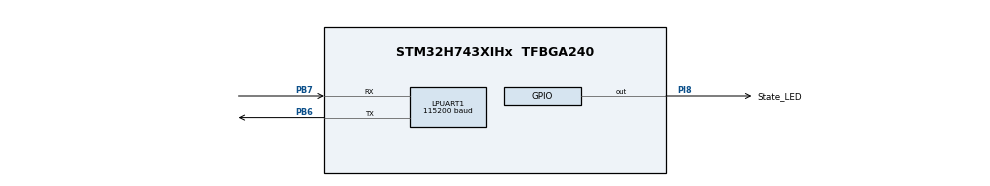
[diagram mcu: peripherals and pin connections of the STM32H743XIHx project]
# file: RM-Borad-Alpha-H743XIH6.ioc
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Bdma.LPUART1_RX.0.Direction=DMA_PERIPH_TO_MEMORY
Bdma.LPUART1_RX.0.EventEnable=DISABLE
Bdma.LPUART1_RX.0.Instance=BDMA_Channel0
Bdma.LPUART1_RX.0.MemDataAlignment=DMA_MDATAALIGN_BYTE
Bdma.LPUART1_RX.0.MemInc=DMA_MINC_ENABLE
Bdma.LPUART1_RX.0.Mode=DMA_NORMAL
Bdma.LPUART1_RX.0.PeriphDataAlignment=DMA_PDATAALIGN_BYTE
Bdma.LPUART1_RX.0.PeriphInc=DMA_PINC_DISABLE
Bdma.LPUART1_RX.0.Polarity=HAL_DMAMUX_REQ_GEN_RISING
Bdma.LPUART1_RX.0.Priority=DMA_PRIORITY_LOW
Bdma.LPUART1_RX.0.RequestNumber=1
Bdma.LPUART1_RX.0.SignalID=NONE
Bdma.LPUART1_RX.0.SyncEnable=DISABLE
Bdma.LPUART1_RX.0.SyncPolarity=HAL_DMAMUX_SYNC_NO_EVENT
Bdma.LPUART1_RX.0.SyncRequestNumber=1
Bdma.LPUART1_RX.0.SyncSignalID=NONE
Bdma.LPUART1_TX.1.Direction=DMA_MEMORY_TO_PERIPH
Bdma.LPUART1_TX.1.EventEnable=DISABLE
Bdma.LPUART1_TX.1.Instance=BDMA_Channel1
Bdma.LPUART1_TX.1.MemDataAlignment=DMA_MDATAALIGN_BYTE
Bdma.LPUART1_TX.1.MemInc=DMA_MINC_ENABLE
Bdma.LPUART1_TX.1.Mode=DMA_NORMAL
Bdma.LPUART1_TX.1.PeriphDataAlignment=DMA_PDATAALIGN_BYTE
Bdma.LPUART1_TX.1.PeriphInc=DMA_PINC_DISABLE
Bdma.LPUART1_TX.1.Polarity=HAL_DMAMUX_REQ_GEN_RISING
Bdma.LPUART1_TX.1.Priority=DMA_PRIORITY_LOW
Bdma.LPUART1_TX.1.RequestNumber=1
Bdma.LPUART1_TX.1.SignalID=NONE
Bdma.LPUART1_TX.1.SyncEnable=DISABLE
Bdma.LPUART1_TX.1.SyncPolarity=HAL_DMAMUX_SYNC_NO_EVENT
Bdma.LPUART1_TX.1.SyncRequestNumber=1
Bdma.LPUART1_TX.1.SyncSignalID=NONE
Bdma.Request0=LPUART1_RX
Bdma.Request1=LPUART1_TX
Bdma.RequestsNb=2
CORTEX_M7.AccessPermission_S-Cortex_Memory_Protection_Unit_Region1_Settings_S=MPU_REGION_FULL_ACCESS
CORTEX_M7.AccessPermission_S-Cortex_Memory_Protection_Unit_Region2_Settings_S=MPU_REGION_FULL_ACCESS
CORTEX_M7.AccessPermission_S-Cortex_Memory_Protection_Unit_Region3_Settings_S=MPU_REGION_FULL_ACCESS
CORTEX_M7.AccessPermission_S-Cortex_Memory_Protection_Unit_Region4_Settings_S=MPU_REGION_FULL_ACCESS
CORTEX_M7.AccessPermission_Spec=MPU_REGION_FULL_ACCESS
CORTEX_M7.BaseAddress_S-Cortex_Memory_Protection_Unit_Region1_Settings_S=0x30000000
CORTEX_M7.BaseAddress_S-Cortex_Memory_Protection_Unit_Region2_Settings_S=0x30020000
CORTEX_M7.BaseAddress_S-Cortex_Memory_Protection_Unit_Region3_Settings_S=0x30040000
CORTEX_M7.BaseAddress_S-Cortex_Memory_Protection_Unit_Region4_Settings_S=0x38000000
CORTEX_M7.BaseAddress_Spec=0x24000000
CORTEX_M7.CPU_DCache=Enabled
CORTEX_M7.CPU_ICache=Enabled
CORTEX_M7.DisableExec_S-Cortex_Memory_Protection_Unit_Region1_Settings_S=MPU_INSTRUCTION_ACCESS_ENABLE
CORTEX_M7.DisableExec_S-Cortex_Memory_Protection_Unit_Region2_Settings_S=MPU_INSTRUCTION_ACCESS_ENABLE
CORTEX_M7.DisableExec_S-Cortex_Memory_Protection_Unit_Region3_Settings_S=MPU_INSTRUCTION_ACCESS_ENABLE
CORTEX_M7.DisableExec_S-Cortex_Memory_Protection_Unit_Region4_Settings_S=MPU_INSTRUCTION_ACCESS_DISABLE
CORTEX_M7.DisableExec_Spec=MPU_INSTRUCTION_ACCESS_DISABLE
CORTEX_M7.Enable_S-Cortex_Memory_Protection_Unit_Region1_Settings_S=MPU_REGION_ENABLE
CORTEX_M7.Enable_S-Cortex_Memory_Protection_Unit_Region2_Settings_S=MPU_REGION_ENABLE
CORTEX_M7.Enable_S-Cortex_Memory_Protection_Unit_Region3_Settings_S=MPU_REGION_ENABLE
CORTEX_M7.Enable_S-Cortex_Memory_Protection_Unit_Region4_Settings_S=MPU_REGION_ENABLE
CORTEX_M7.IsBufferable_S-Cortex_Memory_Protection_Unit_Region1_Settings_S=MPU_ACCESS_NOT_BUFFERABLE
CORTEX_M7.IsBufferable_S-Cortex_Memory_Protection_Unit_Region2_Settings_S=MPU_ACCESS_NOT_BUFFERABLE
CORTEX_M7.IsBufferable_S-Cortex_Memory_Protection_Unit_Region3_Settings_S=MPU_ACCESS_NOT_BUFFERABLE
CORTEX_M7.IsBufferable_S-Cortex_Memory_Protection_Unit_Region4_Settings_S=MPU_ACCESS_NOT_BUFFERABLE
CORTEX_M7.IsBufferable_Spec=MPU_ACCESS_BUFFERABLE
CORTEX_M7.IsCacheable_S-Cortex_Memory_Protection_Unit_Region1_Settings_S=MPU_ACCESS_NOT_CACHEABLE
CORTEX_M7.IsCacheable_S-Cortex_Memory_Protection_Unit_Region2_Settings_S=MPU_ACCESS_NOT_CACHEABLE
CORTEX_M7.IsCacheable_S-Cortex_Memory_Protection_Unit_Region3_Settings_S=MPU_ACCESS_NOT_CACHEABLE
CORTEX_M7.IsCacheable_S-Cortex_Memory_Protection_Unit_Region4_Settings_S=MPU_ACCESS_NOT_CACHEABLE
CORTEX_M7.IsCacheable_Spec=MPU_ACCESS_CACHEABLE
CORTEX_M7.IsShareable_Spec=MPU_ACCESS_NOT_SHAREABLE
CORTEX_M7.Size_S-Cortex_Memory_Protection_Unit_Region1_Settings_S=MPU_REGION_SIZE_128KB
CORTEX_M7.Size_S-Cortex_Memory_Protection_Unit_Region2_Settings_S=MPU_REGION_SIZE_128KB
CORTEX_M7.Size_S-Cortex_Memory_Protection_Unit_Region3_Settings_S=MPU_REGION_SIZE_32KB
CORTEX_M7.Size_S-Cortex_Memory_Protection_Unit_Region4_Settings_S=MPU_REGION_SIZE_64KB
CORTEX_M7.Size_Spec=MPU_REGION_SIZE_512KB
CORTEX_M7.SubRegionDisable_Spec=0
CORTEX_M7.TypeExtField_S-Cortex_Memory_Protection_Unit_Region1_Settings_S=MPU_TEX_LEVEL1
CORTEX_M7.TypeExtField_S-Cortex_Memory_Protection_Unit_Region2_Settings_S=MPU_TEX_LEVEL1
CORTEX_M7.TypeExtField_S-Cortex_Memory_Protection_Unit_Region3_Settings_S=MPU_TEX_LEVEL1
CORTEX_M7.TypeExtField_S-Cortex_Memory_Protection_Unit_Region4_Settings_S=MPU_TEX_LEVEL1
CORTEX_M7.TypeExtField_Spec=MPU_TEX_LEVEL1
CORTEX_M7.default_mode_Activation=1
FREERTOS.Tasks01=StateLED_Task,16,128,Start_StateLED_Toggle,As weak,NULL,Dynamic,NULL,NULL;Debug_Task,24,256,Start_Debug_Task,As weak,NULL,Dynamic,NULL,NULL;IWDG_Task,32,128,Start_IWDG_Refresh,As weak,NULL,Dynamic,NULL,NULL;Shell_Task,16,1024,Start_Latter_Shell,As weak,NULL,Dynamic,NULL,NULL
FREERTOS.configENABLE_FPU=1
FREERTOS.configGENERATE_RUN_TIME_STATS=1
FREERTOS.configUSE_NEWLIB_REENTRANT=1
LPUART1.BaudRate=115200
Mcu.Family=STM32H7
Mcu.Name=STM32H743XIHx
Mcu.Package=TFBGA240
NVIC.BDMA_Channel0_IRQn=true\:5\:0\:false\:false\:true\:true\:false\:true\:true
NVIC.BDMA_Channel1_IRQn=true\:5\:0\:false\:false\:true\:true\:false\:true\:true
NVIC.PriorityGroup=NVIC_PRIORITYGROUP_4
NVIC.TIM17_IRQn=true\:15\:0\:false\:false\:true\:false\:false\:true\:true
NVIC.TimeBase=TIM17_IRQn
NVIC.TimeBaseIP=TIM17
PA0.PinAttribute=Free
PA0.Signal=S_TIM2_CH1_ETR
PA0_C.Signal=ADCx_INN1
PA1.PinAttribute=Free
PA1.Signal=S_TIM2_CH2
PA10.PinAttribute=Free
PA10.Signal=HRTIM_CHC2
PA11.Signal=HRTIM_CHD1
PA12.Signal=HRTIM_CHD2
PA13\ (JTMS/SWDIO).Mode=Serial_Wire
PA13\ (JTMS/SWDIO).PinAttribute=Free
PA13\ (JTMS/SWDIO).Signal=DEBUG_JTMS-SWDIO
PA14\ (JTCK/SWCLK).Mode=Serial_Wire
PA14\ (JTCK/SWCLK).Signal=DEBUG_JTCK-SWCLK
PA15\ (JTDI).Signal=UART7_TX
PA1_C.Signal=ADCx_INP1
PA2.PinAttribute=Free
PA2.Signal=S_TIM2_CH3
PA3.Signal=USART2_RX
PA4.Signal=COMP_DAC11_group
PA5.Signal=COMP_DAC12_group
PA6.Signal=SPI6_MISO
PA7.Signal=TIM8_CH1N
PA8.Signal=HRTIM_CHB2
PA9.Signal=HRTIM_CHC1
PB0.Signal=OPAMP1_VINP
PB1.Signal=COMP1_INM
PB10.Signal=QUADSPI_BK1_NCS
PB11.Signal=S_TIM2_CH4
PB12.Signal=FDCAN2_RX
PB13.Signal=FDCAN2_TX
PB14.Signal=USART1_TX
PB15.Signal=USART1_RX
PB2.Signal=COMP1_INP
PB3\ (JTDO/TRACESWO).PinAttribute=Free
PB3\ (JTDO/TRACESWO).Signal=SPI3_SCK
PB4\ (NJTRST).Signal=SPI1_MISO
PB5.Signal=SPI6_MOSI
PB6.Mode=Asynchronous
PB6.Signal=LPUART1_TX
PB7.Mode=Asynchronous
PB7.PinAttribute=Free
PB7.Signal=LPUART1_RX
PB8.PinAttribute=Free
PB8.Signal=I2C1_SCL
PB9.PinAttribute=Free
PB9.Signal=I2C1_SDA
PC0.Signal=ADCx_INP10
PC1.Signal=ADCx_INN10
PC10.Signal=QUADSPI_BK1_IO1
PC11.Signal=SPI3_MISO
PC12.PinAttribute=Free
PC12.Signal=UART5_TX
PC14-OSC32_IN\ (OSC32_IN).Mode=LSE-External-Oscillator
PC14-OSC32_IN\ (OSC32_IN).Signal=RCC_OSC32_IN
PC15-OSC32_OUT\ (OSC32_OUT).Mode=LSE-External-Oscillator
PC15-OSC32_OUT\ (OSC32_OUT).Signal=RCC_OSC32_OUT
PC2.Signal=ADCx_INP12
PC2_C.Signal=ADC3_INN1
PC3.Signal=ADCx_INN12
PC3_C.Signal=ADC3_INP1
PC4.Signal=OPAMP1_VOUT
PC5.Signal=OPAMP1_VINM
PC6.Signal=HRTIM_CHA1
PC7.Signal=HRTIM_CHA2
PC8.Signal=HRTIM_CHB1
PC9.Signal=QUADSPI_BK1_IO0
PD0.PinAttribute=Free
PD0.Signal=FDCAN1_RX
PD1.Signal=UART4_TX
PD11.Signal=LPTIM2_IN2
PD12.Signal=LPTIM2_IN1
PD13.Signal=QUADSPI_BK1_IO3
PD2.PinAttribute=Free
PD2.Signal=UART5_RX
PD5.Signal=USART2_TX
PD6.Signal=SPI3_MOSI
PD7.PinAttribute=Free
PD7.Signal=SPI1_MOSI
PD8.Signal=USART3_TX
PD9.Signal=USART3_RX
PE0.Signal=UART8_RX
PE1.Signal=UART8_TX
PE10.PinAttribute=Free
PE10.Signal=COMP2_INM
PE11.Signal=COMP2_INP
PE12.Signal=COMP1_OUT
PE13.Signal=SPI4_MISO
PE2.Signal=SPI4_SCK
PE6.Signal=SPI4_MOSI
PE7.Signal=OPAMP2_VOUT
PE8.Signal=COMP2_OUT
PE9.Signal=OPAMP2_VINP
PF0.Signal=I2C2_SDA
PF1.Signal=I2C2_SCL
PF10.Signal=QUADSPI_CLK
PF11.Signal=ADC1_INP2
PF12.Signal=ADC1_INN2
PF14.Signal=I2C4_SCL
PF15.Signal=I2C4_SDA
PF3.Signal=ADC3_INP5
PF4.Signal=ADC3_INN5
PF6.Signal=UART7_RX
PF7.Signal=QUADSPI_BK1_IO2
PF8.Signal=SPI5_MISO
PF9.Signal=SPI5_MOSI
PG1.Signal=OPAMP2_VINM
PG11.Signal=SPI1_SCK
PG12.PinAttribute=Free
PG12.Signal=LPTIM1_IN1
PG13.PinAttribute=Free
PG13.Signal=SPI6_SCK
PG14.PinAttribute=Free
PG14.Signal=USART6_TX
PG6.Signal=HRTIM_CHE1
PG7.Signal=HRTIM_CHE2
PG9.Signal=USART6_RX
PH0-OSC_IN\ (PH0).Mode=HSE-External-Oscillator
PH0-OSC_IN\ (PH0).Signal=RCC_OSC_IN
PH1-OSC_OUT\ (PH1).Mode=HSE-External-Oscillator
PH1-OSC_OUT\ (PH1).Signal=RCC_OSC_OUT
PH10.Signal=S_TIM5_CH1
PH11.Signal=S_TIM5_CH2
PH12.Signal=S_TIM5_CH3
PH13.Signal=FDCAN1_TX
PH14.Signal=TIM8_CH2N
PH15.Signal=TIM8_CH3N
PH2.Signal=LPTIM1_IN2
PH3.PinAttribute=Free
PH3.Signal=ADC3_INP14
PH4.Signal=ADC3_INP15
PH5.Signal=ADC3_INN15
PH6.Signal=SPI5_SCK
PH7.Signal=I2C3_SCL
PH8.Signal=I2C3_SDA
PI0.Signal=S_TIM5_CH4
PI1.Signal=SPI2_SCK
PI2.Signal=SPI2_MISO
PI3.PinAttribute=Free
PI3.Signal=SPI2_MOSI
PI5.Signal=S_TIM8_CH1
PI6.Signal=S_TIM8_CH2
PI7.Signal=S_TIM8_CH3
PI8.GPIO_Label=State_LED
PI8.Signal=GPIO_Output
PI9.Signal=UART4_RX
PJ10.Signal=TIM1_CH2N
PJ11.Signal=S_TIM1_CH2
PJ8.PinAttribute=Free
PJ8.Signal=TIM1_CH3N
PJ9.Signal=S_TIM1_CH3
PK0.Signal=TIM1_CH1N
PK1.Signal=S_TIM1_CH1
ProjectManager.HeapSize=0x200
ProjectManager.StackSize=0x400
ProjectManager.TargetToolchain=STM32CubeIDE
RCC.ADCCLockSelection=RCC_ADCCLKSOURCE_PLL3
RCC.ADCFreq_Value=75000000
RCC.APB1Freq_Value=50000000
RCC.APB2Freq_Value=50000000
RCC.APB3Freq_Value=50000000
RCC.APB4Freq_Value=50000000
RCC.CortexFreq_Value=100000000
RCC.D1PPRE=RCC_APB3_DIV2
RCC.D2PPRE1=RCC_APB1_DIV2
RCC.D2PPRE2=RCC_APB2_DIV2
RCC.D3PPRE=RCC_APB4_DIV2
RCC.DIVM1=2
RCC.DIVM2=2
RCC.DIVM3=2
RCC.DIVN1=16
RCC.DIVN2=12
RCC.DIVN3=12
RCC.DIVQ2=3
RCC.DIVR1=1
RCC.EnbaleCSS=false
RCC.FDCANCLockSelection=RCC_FDCANCLKSOURCE_PLL2
RCC.HCLKFreq_Value=100000000
RCC.PLL1_VCI_Range-AdvancedSettings=RCC_PLL1VCIRANGE_0
RCC.PLL2FRACN=0
RCC.PLL2_VCI_Range-AdvancedSettings=RCC_PLL2VCIRANGE_3
RCC.PLL3FRACN=0
RCC.PLL3_VCI_Range-AdvancedSettings=RCC_PLL3VCIRANGE_0
RCC.PLL3_VCO_SEL-AdvancedSettings=RCC_PLL3VCOMEDIUM
RCC.PLLFRACN=0
RCC.PLLSourceVirtual=RCC_PLLSOURCE_HSE
RCC.PWR_Regulator_Voltage_Scale=PWR_REGULATOR_VOLTAGE_SCALE3
RCC.RTCClockSelection=RCC_RTCCLKSOURCE_LSE
RCC.SYSCLKFreq_VALUE=100000000
RCC.SYSCLKSource=RCC_SYSCLKSOURCE_PLLCLK
RCC.SupplySource=PWR_LDO_SUPPLY
RCC.Tim2Mul=2
RCC.USBFreq_Value=100000000
SH.ADCx_INN1.0=ADC1_INN1
SH.ADCx_INN1.1=ADC2_INN1
SH.ADCx_INN10.0=ADC3_INN10
SH.ADCx_INN10.1=ADC2_INN10
SH.ADCx_INN10.2=ADC1_INN10
SH.ADCx_INN12.0=ADC1_INN12
SH.ADCx_INN12.1=ADC2_INN12
SH.ADCx_INP1.0=ADC1_INP1
SH.ADCx_INP1.1=ADC2_INP1
SH.ADCx_INP10.0=ADC3_INP10
SH.ADCx_INP10.1=ADC2_INP10
SH.ADCx_INP10.2=ADC1_INP10
SH.ADCx_INP12.0=ADC1_INP12
SH.ADCx_INP12.1=ADC2_INP12
SH.COMP_DAC11_group.0=DAC1_OUT1
SH.COMP_DAC12_group.0=DAC1_OUT2
SH.S_TIM1_CH1.0=TIM1_CH1
SH.S_TIM1_CH2.0=TIM1_CH2
SH.S_TIM1_CH3.0=TIM1_CH3
SH.S_TIM2_CH1_ETR.0=TIM2_CH1
SH.S_TIM2_CH2.0=TIM2_CH2
SH.S_TIM2_CH3.0=TIM2_CH3
SH.S_TIM2_CH4.0=TIM2_CH4
SH.S_TIM5_CH1.0=TIM5_CH1
SH.S_TIM5_CH2.0=TIM5_CH2
SH.S_TIM5_CH3.0=TIM5_CH3
SH.S_TIM5_CH4.0=TIM5_CH4
SH.S_TIM8_CH1.0=TIM8_CH1
SH.S_TIM8_CH2.0=TIM8_CH2
SH.S_TIM8_CH3.0=TIM8_CH3
VP_FREERTOS_VS_CMSIS_V2.Mode=CMSIS_V2
VP_IWDG1_VS_IWDG.Mode=IWDG_Activate
VP_MEMORYMAP_VS_MEMORYMAP.Mode=CurAppReg
VP_SYS_VS_tim17.Mode=TIM17
board=custom

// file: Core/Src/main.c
/* USER CODE BEGIN Header */
/**
  ******************************************************************************
  * @file           : main.c
  * @brief          : Main program body
  ******************************************************************************
  * @attention
  *
  * Copyright (c) 2026 STMicroelectronics.
  * All rights reserved.
  *
  * This software is licensed under terms that can be found in the LICENSE file
  * in the root directory of this software component.
  * If no LICENSE file comes with this software, it is provided AS-IS.
  *
  ******************************************************************************
  */
/* USER CODE END Header */
#include "main.h"
#include "FreeRTOS.h"
#include "cmsis_os2.h"

/* USER CODE BEGIN Includes */
#ifdef DEBUG
#include "transport/user_rtt.h"
#endif

/* USER CODE END Includes */

IWDG_HandleTypeDef hiwdg1;

UART_HandleTypeDef hlpuart1;
DMA_HandleTypeDef hdma_lpuart1_rx;
DMA_HandleTypeDef hdma_lpuart1_tx;

/* Definitions for StateLED_Task */
osThreadId_t StateLED_TaskHandle;
const osThreadAttr_t StateLED_Task_attributes = {
  .name = "StateLED_Task",
  .stack_size = 128 * 4,
  .priority = (osPriority_t) osPriorityBelowNormal,
};
/* Definitions for Debug_Task */
osThreadId_t Debug_TaskHandle;
const osThreadAttr_t Debug_Task_attributes = {
  .name = "Debug_Task",
  .stack_size = 256 * 4,
  .priority = (osPriority_t) osPriorityNormal,
};
/* Definitions for IWDG_Task */
osThreadId_t IWDG_TaskHandle;
const osThreadAttr_t IWDG_Task_attributes = {
  .name = "IWDG_Task",
  .stack_size = 128 * 4,
  .priority = (osPriority_t) osPriorityAboveNormal,
};
/* Definitions for Shell_Task */
osThreadId_t Shell_TaskHandle;
const osThreadAttr_t Shell_Task_attributes = {
  .name = "Shell_Task",
  .stack_size = 1024 * 4,
  .priority = (osPriority_t) osPriorityBelowNormal,
};

void SystemClock_Config(void);
static void MPU_Config(void);
static void MX_GPIO_Init(void);
static void MX_BDMA_Init(void);
static void MX_IWDG1_Init(void);
static void MX_LPUART1_UART_Init(void);
void Start_StateLED_Toggle(void *argument);
void Start_Debug_Task(void *argument);
void Start_IWDG_Refresh(void *argument);
void Start_Latter_Shell(void *argument);

/* USER CODE BEGIN 0 */
__weak void BSP_Init(void);

/* USER CODE END 0 */

int main(void)
{

  /* MPU Configuration--------------------------------------------------------*/
  MPU_Config();

  /* Enable the CPU Cache */

  /* Enable I-Cache---------------------------------------------------------*/
  SCB_EnableICache();

  /* Enable D-Cache---------------------------------------------------------*/
  SCB_EnableDCache();

  /* MCU Configuration--------------------------------------------------------*/

  /* Reset of all peripherals, Initializes the Flash interface and the Systick. */
  HAL_Init();

  /* USER CODE BEGIN Init */

  /* Enable ITCM */
  SCB->ITCMCR |= SCB_ITCMCR_EN_Msk | SCB_ITCMCR_RETEN_Msk;
  __DSB();
  __ISB();

  /* USER CODE END Init */

  /* Configure the system clock */
  SystemClock_Config();

  /* Initialize all configured peripherals */
  MX_GPIO_Init();
  MX_BDMA_Init();
  MX_IWDG1_Init();
  MX_LPUART1_UART_Init();
  /* USER CODE BEGIN 2 */
  BSP_Init();

  /* USER CODE END 2 */

  /* Init scheduler */
  osKernelInitialize();

  /* Create the thread(s) */
  /* creation of StateLED_Task */
  StateLED_TaskHandle = osThreadNew(Start_StateLED_Toggle, NULL, &StateLED_Task_attributes);

  /* creation of Debug_Task */
  Debug_TaskHandle = osThreadNew(Start_Debug_Task, NULL, &Debug_Task_attributes);

  /* creation of IWDG_Task */
  IWDG_TaskHandle = osThreadNew(Start_IWDG_Refresh, NULL, &IWDG_Task_attributes);

  /* creation of Shell_Task */
  Shell_TaskHandle = osThreadNew(Start_Latter_Shell, NULL, &Shell_Task_attributes);

  /* Start scheduler */
  osKernelStart();

  /* We should never get here as control is now taken by the scheduler */

  /* Infinite loop */
  while (1)
  {

  }
}

void SystemClock_Config(void)
{
  RCC_OscInitTypeDef RCC_OscInitStruct = {0};
  RCC_ClkInitTypeDef RCC_ClkInitStruct = {0};

  /** Supply configuration update enable
  */
  HAL_PWREx_ConfigSupply(PWR_LDO_SUPPLY);

  /** Configure the main internal regulator output voltage
  */
  __HAL_PWR_VOLTAGESCALING_CONFIG(PWR_REGULATOR_VOLTAGE_SCALE3);

  while(!__HAL_PWR_GET_FLAG(PWR_FLAG_VOSRDY)) {}

  /** Initializes the RCC Oscillators according to the specified parameters
  * in the RCC_OscInitTypeDef structure.
  */
  RCC_OscInitStruct.OscillatorType = RCC_OSCILLATORTYPE_LSI|RCC_OSCILLATORTYPE_HSE;
  RCC_OscInitStruct.HSEState = RCC_HSE_ON;
  RCC_OscInitStruct.LSIState = RCC_LSI_ON;
  RCC_OscInitStruct.PLL.PLLState = RCC_PLL_ON;
  RCC_OscInitStruct.PLL.PLLSource = RCC_PLLSOURCE_HSE;
  RCC_OscInitStruct.PLL.PLLM = 2;
  RCC_OscInitStruct.PLL.PLLN = 16;
  RCC_OscInitStruct.PLL.PLLP = 2;
  RCC_OscInitStruct.PLL.PLLQ = 2;
  RCC_OscInitStruct.PLL.PLLR = 1;
  RCC_OscInitStruct.PLL.PLLRGE = RCC_PLL1VCIRANGE_3;
  RCC_OscInitStruct.PLL.PLLVCOSEL = RCC_PLL1VCOWIDE;
  RCC_OscInitStruct.PLL.PLLFRACN = 0;
  if (HAL_RCC_OscConfig(&RCC_OscInitStruct) != HAL_OK)
  {
    Error_Handler();
  }

  /** Initializes the CPU, AHB and APB buses clocks
  */
  RCC_ClkInitStruct.ClockType = RCC_CLOCKTYPE_HCLK|RCC_CLOCKTYPE_SYSCLK
                              |RCC_CLOCKTYPE_PCLK1|RCC_CLOCKTYPE_PCLK2
                              |RCC_CLOCKTYPE_D3PCLK1|RCC_CLOCKTYPE_D1PCLK1;
  RCC_ClkInitStruct.SYSCLKSource = RCC_SYSCLKSOURCE_PLLCLK;
  RCC_ClkInitStruct.SYSCLKDivider = RCC_SYSCLK_DIV1;
  RCC_ClkInitStruct.AHBCLKDivider = RCC_HCLK_DIV1;
  RCC_ClkInitStruct.APB3CLKDivider = RCC_APB3_DIV2;
  RCC_ClkInitStruct.APB1CLKDivider = RCC_APB1_DIV2;
  RCC_ClkInitStruct.APB2CLKDivider = RCC_APB2_DIV2;
  RCC_ClkInitStruct.APB4CLKDivider = RCC_APB4_DIV2;

  if (HAL_RCC_ClockConfig(&RCC_ClkInitStruct, FLASH_LATENCY_2) != HAL_OK)
  {
    Error_Handler();
  }
}

static void MX_IWDG1_Init(void)
{

  hiwdg1.Instance = IWDG1;
  hiwdg1.Init.Prescaler = IWDG_PRESCALER_4;
  hiwdg1.Init.Window = 4095;
  hiwdg1.Init.Reload = 4095;
  if (HAL_IWDG_Init(&hiwdg1) != HAL_OK)
  {
    Error_Handler();
  }

}

static void MX_LPUART1_UART_Init(void)
{

  hlpuart1.Instance = LPUART1;
  hlpuart1.Init.BaudRate = 115200;
  hlpuart1.Init.WordLength = UART_WORDLENGTH_8B;
  hlpuart1.Init.StopBits = UART_STOPBITS_1;
  hlpuart1.Init.Parity = UART_PARITY_NONE;
  hlpuart1.Init.Mode = UART_MODE_TX_RX;
  hlpuart1.Init.HwFlowCtl = UART_HWCONTROL_NONE;
  hlpuart1.Init.OneBitSampling = UART_ONE_BIT_SAMPLE_DISABLE;
  hlpuart1.Init.ClockPrescaler = UART_PRESCALER_DIV1;
  hlpuart1.AdvancedInit.AdvFeatureInit = UART_ADVFEATURE_NO_INIT;
  hlpuart1.FifoMode = UART_FIFOMODE_DISABLE;
  if (HAL_UART_Init(&hlpuart1) != HAL_OK)
  {
    Error_Handler();
  }
  if (HAL_UARTEx_SetTxFifoThreshold(&hlpuart1, UART_TXFIFO_THRESHOLD_1_8) != HAL_OK)
  {
    Error_Handler();
  }
  if (HAL_UARTEx_SetRxFifoThreshold(&hlpuart1, UART_RXFIFO_THRESHOLD_1_8) != HAL_OK)
  {
    Error_Handler();
  }
  if (HAL_UARTEx_DisableFifoMode(&hlpuart1) != HAL_OK)
  {
    Error_Handler();
  }

}

static void MX_BDMA_Init(void)
{

  /* DMA controller clock enable */
  __HAL_RCC_BDMA_CLK_ENABLE();

  /* DMA interrupt init */
  /* BDMA_Channel0_IRQn interrupt configuration */
  HAL_NVIC_SetPriority(BDMA_Channel0_IRQn, 5, 0);
  HAL_NVIC_EnableIRQ(BDMA_Channel0_IRQn);
  /* BDMA_Channel1_IRQn interrupt configuration */
  HAL_NVIC_SetPriority(BDMA_Channel1_IRQn, 5, 0);
  HAL_NVIC_EnableIRQ(BDMA_Channel1_IRQn);

}

static void MX_GPIO_Init(void)
{
  GPIO_InitTypeDef GPIO_InitStruct = {0};

  /* GPIO Ports Clock Enable */
  __HAL_RCC_GPIOI_CLK_ENABLE();
  __HAL_RCC_GPIOB_CLK_ENABLE();
  __HAL_RCC_GPIOK_CLK_ENABLE();
  __HAL_RCC_GPIOG_CLK_ENABLE();
  __HAL_RCC_GPIOD_CLK_ENABLE();
  __HAL_RCC_GPIOC_CLK_ENABLE();
  __HAL_RCC_GPIOA_CLK_ENABLE();
  __HAL_RCC_GPIOE_CLK_ENABLE();
  __HAL_RCC_GPIOJ_CLK_ENABLE();
  __HAL_RCC_GPIOH_CLK_ENABLE();
  __HAL_RCC_GPIOF_CLK_ENABLE();

  /*Configure GPIO pin Output Level */
  HAL_GPIO_WritePin(State_LED_GPIO_Port, State_LED_Pin, GPIO_PIN_RESET);

  /*Configure GPIO pins : PI6 PI5 PI7 */
  GPIO_InitStruct.Pin = GPIO_PIN_6|GPIO_PIN_5|GPIO_PIN_7;
  GPIO_InitStruct.Mode = GPIO_MODE_AF_PP;
  GPIO_InitStruct.Pull = GPIO_NOPULL;
  GPIO_InitStruct.Speed = GPIO_SPEED_FREQ_LOW;
  GPIO_InitStruct.Alternate = GPIO_AF3_TIM8;
  HAL_GPIO_Init(GPIOI, &GPIO_InitStruct);

  /*Configure GPIO pins : PI4 PI10 PI11 PI12
                           PI13 PI14 PI15 */
  GPIO_InitStruct.Pin = GPIO_PIN_4|GPIO_PIN_10|GPIO_PIN_11|GPIO_PIN_12
                          |GPIO_PIN_13|GPIO_PIN_14|GPIO_PIN_15;
  GPIO_InitStruct.Mode = GPIO_MODE_ANALOG;
  GPIO_InitStruct.Pull = GPIO_NOPULL;
  HAL_GPIO_Init(GPIOI, &GPIO_InitStruct);

  /*Configure GPIO pin : PB5 */
  GPIO_InitStruct.Pin = GPIO_PIN_5;
  GPIO_InitStruct.Mode = GPIO_MODE_AF_PP;
  GPIO_InitStruct.Pull = GPIO_NOPULL;
  GPIO_InitStruct.Speed = GPIO_SPEED_FREQ_LOW;
  GPIO_InitStruct.Alternate = GPIO_AF8_SPI6;
  HAL_GPIO_Init(GPIOB, &GPIO_InitStruct);

  /*Configure GPIO pins : PK5 PK4 PK6 PK3
                           PK7 PK2 */
  GPIO_InitStruct.Pin = GPIO_PIN_5|GPIO_PIN_4|GPIO_PIN_6|GPIO_PIN_3
                          |GPIO_PIN_7|GPIO_PIN_2;
  GPIO_InitStruct.Mode = GPIO_MODE_ANALOG;
  GPIO_InitStruct.Pull = GPIO_NOPULL;
  HAL_GPIO_Init(GPIOK, &GPIO_InitStruct);

  /*Configure GPIO pins : PG10 PG15 PG8 PG5
                           PG4 PG3 PG2 PG0
                           PG1 */
  GPIO_InitStruct.Pin = GPIO_PIN_10|GPIO_PIN_15|GPIO_PIN_8|GPIO_PIN_5
                          |GPIO_PIN_4|GPIO_PIN_3|GPIO_PIN_2|GPIO_PIN_0
                          |GPIO_PIN_1;
  GPIO_InitStruct.Mode = GPIO_MODE_ANALOG;
  GPIO_InitStruct.Pull = GPIO_NOPULL;
  HAL_GPIO_Init(GPIOG, &GPIO_InitStruct);

  /*Configure GPIO pins : PG9 PG14 */
  GPIO_InitStruct.Pin = GPIO_PIN_9|GPIO_PIN_14;
  GPIO_InitStruct.Mode = GPIO_MODE_AF_PP;
  GPIO_InitStruct.Pull = GPIO_NOPULL;
  GPIO_InitStruct.Speed = GPIO_SPEED_FREQ_LOW;
  GPIO_InitStruct.Alternate = GPIO_AF7_USART6;
  HAL_GPIO_Init(GPIOG, &GPIO_InitStruct);

  /*Configure GPIO pin : PD5 */
  GPIO_InitStruct.Pin = GPIO_PIN_5;
  GPIO_InitStruct.Mode = GPIO_MODE_AF_PP;
  GPIO_InitStruct.Pull = GPIO_NOPULL;
  GPIO_InitStruct.Speed = GPIO_SPEED_FREQ_LOW;
  GPIO_InitStruct.Alternate = GPIO_AF7_USART2;
  HAL_GPIO_Init(GPIOD, &GPIO_InitStruct);

  /*Configure GPIO pins : PD4 PD3 PD15 PD14
                           PD10 */
  GPIO_InitStruct.Pin = GPIO_PIN_4|GPIO_PIN_3|GPIO_PIN_15|GPIO_PIN_14
                          |GPIO_PIN_10;
  GPIO_InitStruct.Mode = GPIO_MODE_ANALOG;
  GPIO_InitStruct.Pull = GPIO_NOPULL;
  HAL_GPIO_Init(GPIOD, &GPIO_InitStruct);

  /*Configure GPIO pins : PC10 PC9 */
  GPIO_InitStruct.Pin = GPIO_PIN_10|GPIO_PIN_9;
  GPIO_InitStruct.Mode = GPIO_MODE_AF_PP;
  GPIO_InitStruct.Pull = GPIO_NOPULL;
  GPIO_InitStruct.Speed = GPIO_SPEED_FREQ_LOW;
  GPIO_InitStruct.Alternate = GPIO_AF9_QUADSPI;
  HAL_GPIO_Init(GPIOC, &GPIO_InitStruct);

  /*Configure GPIO pin : PA15 */
  GPIO_InitStruct.Pin = GPIO_PIN_15;
  GPIO_InitStruct.Mode = GPIO_MODE_AF_PP;
  GPIO_InitStruct.Pull = GPIO_NOPULL;
  GPIO_InitStruct.Speed = GPIO_SPEED_FREQ_LOW;
  GPIO_InitStruct.Alternate = GPIO_AF11_UART7;
  HAL_GPIO_Init(GPIOA, &GPIO_InitStruct);

  /*Configure GPIO pins : PI1 PI2 PI3 */
  GPIO_InitStruct.Pin = GPIO_PIN_1|GPIO_PIN_2|GPIO_PIN_3;
  GPIO_InitStruct.Mode = GPIO_MODE_AF_PP;
  GPIO_InitStruct.Pull = GPIO_NOPULL;
  GPIO_InitStruct.Speed = GPIO_SPEED_FREQ_LOW;
  GPIO_InitStruct.Alternate = GPIO_AF5_SPI2;
  HAL_GPIO_Init(GPIOI, &GPIO_InitStruct);

  /*Configure GPIO pin : PI0 */
  GPIO_InitStruct.Pin = GPIO_PIN_0;
  GPIO_InitStruct.Mode = GPIO_MODE_AF_PP;
  GPIO_InitStruct.Pull = GPIO_NOPULL;
  GPIO_InitStruct.Speed = GPIO_SPEED_FREQ_LOW;
  GPIO_InitStruct.Alternate = GPIO_AF2_TIM5;
  HAL_GPIO_Init(GPIOI, &GPIO_InitStruct);

  /*Configure GPIO pins : PE1 PE0 */
  GPIO_InitStruct.Pin = GPIO_PIN_1|GPIO_PIN_0;
  GPIO_InitStruct.Mode = GPIO_MODE_AF_PP;
  GPIO_InitStruct.Pull = GPIO_NOPULL;
  GPIO_InitStruct.Speed = GPIO_SPEED_FREQ_LOW;
  GPIO_InitStruct.Alternate = GPIO_AF8_UART8;
  HAL_GPIO_Init(GPIOE, &GPIO_InitStruct);

  /*Configure GPIO pin : PB4 */
  GPIO_InitStruct.Pin = GPIO_PIN_4;
  GPIO_InitStruct.Mode = GPIO_MODE_AF_PP;
  GPIO_InitStruct.Pull = GPIO_NOPULL;
  GPIO_InitStruct.Speed = GPIO_SPEED_FREQ_LOW;
  GPIO_InitStruct.Alternate = GPIO_AF5_SPI1;
  HAL_GPIO_Init(GPIOB, &GPIO_InitStruct);

  /*Configure GPIO pin : PG11 */
  GPIO_InitStruct.Pin = GPIO_PIN_11;
  GPIO_InitStruct.Mode = GPIO_MODE_AF_PP;
  GPIO_InitStruct.Pull = GPIO_NOPULL;
  GPIO_InitStruct.Speed = GPIO_SPEED_FREQ_LOW;
  GPIO_InitStruct.Alternate = GPIO_AF5_SPI1;
  HAL_GPIO_Init(GPIOG, &GPIO_InitStruct);

  /*Configure GPIO pins : PJ15 PJ14 PJ12 PJ13
                           PJ0 PJ7 PJ6 PJ1
                           PJ5 PJ2 PJ3 PJ4 */
  GPIO_InitStruct.Pin = GPIO_PIN_15|GPIO_PIN_14|GPIO_PIN_12|GPIO_PIN_13
                          |GPIO_PIN_0|GPIO_PIN_7|GPIO_PIN_6|GPIO_PIN_1
                          |GPIO_PIN_5|GPIO_PIN_2|GPIO_PIN_3|GPIO_PIN_4;
  GPIO_InitStruct.Mode = GPIO_MODE_ANALOG;
  GPIO_InitStruct.Pull = GPIO_NOPULL;
  HAL_GPIO_Init(GPIOJ, &GPIO_InitStruct);

  /*Configure GPIO pin : PD6 */
  GPIO_InitStruct.Pin = GPIO_PIN_6;
  GPIO_InitStruct.Mode = GPIO_MODE_AF_PP;
  GPIO_InitStruct.Pull = GPIO_NOPULL;
  GPIO_InitStruct.Speed = GPIO_SPEED_FREQ_LOW;
  GPIO_InitStruct.Alternate = GPIO_AF5_SPI3;
  HAL_GPIO_Init(GPIOD, &GPIO_InitStruct);

  /*Configure GPIO pin : PC11 */
  GPIO_InitStruct.Pin = GPIO_PIN_11;
  GPIO_InitStruct.Mode = GPIO_MODE_AF_PP;
  GPIO_InitStruct.Pull = GPIO_NOPULL;
  GPIO_InitStruct.Speed = GPIO_SPEED_FREQ_LOW;
  GPIO_InitStruct.Alternate = GPIO_AF6_SPI3;
  HAL_GPIO_Init(GPIOC, &GPIO_InitStruct);

  /*Configure GPIO pins : PH15 PH14 */
  GPIO_InitStruct.Pin = GPIO_PIN_15|GPIO_PIN_14;
  GPIO_InitStruct.Mode = GPIO_MODE_AF_PP;
  GPIO_InitStruct.Pull = GPIO_NOPULL;
  GPIO_InitStruct.Speed = GPIO_SPEED_FREQ_LOW;
  GPIO_InitStruct.Alternate = GPIO_AF3_TIM8;
  HAL_GPIO_Init(GPIOH, &GPIO_InitStruct);

  /*Configure GPIO pins : PE2 PE6 PE13 */
  GPIO_InitStruct.Pin = GPIO_PIN_2|GPIO_PIN_6|GPIO_PIN_13;
  GPIO_InitStruct.Mode = GPIO_MODE_AF_PP;
  GPIO_InitStruct.Pull = GPIO_NOPULL;
  GPIO_InitStruct.Speed = GPIO_SPEED_FREQ_LOW;
  GPIO_InitStruct.Alternate = GPIO_AF5_SPI4;
  HAL_GPIO_Init(GPIOE, &GPIO_InitStruct);

  /*Configure GPIO pin : PB3 */
  GPIO_InitStruct.Pin = GPIO_PIN_3;
  GPIO_InitStruct.Mode = GPIO_MODE_AF_PP;
  GPIO_InitStruct.Pull = GPIO_NOPULL;
  GPIO_InitStruct.Speed = GPIO_SPEED_FREQ_LOW;
  GPIO_InitStruct.Alternate = GPIO_AF6_SPI3;
  HAL_GPIO_Init(GPIOB, &GPIO_InitStruct);

  /*Configure GPIO pin : PG12 */
  GPIO_InitStruct.Pin = GPIO_PIN_12;
  GPIO_InitStruct.Mode = GPIO_MODE_AF_PP;
  GPIO_InitStruct.Pull = GPIO_NOPULL;
  GPIO_InitStruct.Speed = GPIO_SPEED_FREQ_LOW;
  GPIO_InitStruct.Alternate = GPIO_AF1_LPTIM1;
  HAL_GPIO_Init(GPIOG, &GPIO_InitStruct);

  /*Configure GPIO pin : PD7 */
  GPIO_InitStruct.Pin = GPIO_PIN_7;
  GPIO_InitStruct.Mode = GPIO_MODE_AF_PP;
  GPIO_InitStruct.Pull = GPIO_NOPULL;
  GPIO_InitStruct.Speed = GPIO_SPEED_FREQ_LOW;
  GPIO_InitStruct.Alternate = GPIO_AF5_SPI1;
  HAL_GPIO_Init(GPIOD, &GPIO_InitStruct);

  /*Configure GPIO pin : PC12 */
  GPIO_InitStruct.Pin = GPIO_PIN_12;
  GPIO_InitStruct.Mode = GPIO_MODE_AF_PP;
  GPIO_InitStruct.Pull = GPIO_NOPULL;
  GPIO_InitStruct.Speed = GPIO_SPEED_FREQ_LOW;
  GPIO_InitStruct.Alternate = GPIO_AF8_UART5;
  HAL_GPIO_Init(GPIOC, &GPIO_InitStruct);

  /*Configure GPIO pins : PE5 PE4 PE3 PE10
                           PE9 PE11 PE15 PE7
                           PE14 */
  GPIO_InitStruct.Pin = GPIO_PIN_5|GPIO_PIN_4|GPIO_PIN_3|GPIO_PIN_10
                          |GPIO_PIN_9|GPIO_PIN_11|GPIO_PIN_15|GPIO_PIN_7
                          |GPIO_PIN_14;
  GPIO_InitStruct.Mode = GPIO_MODE_ANALOG;
  GPIO_InitStruct.Pull = GPIO_NOPULL;
  HAL_GPIO_Init(GPIOE, &GPIO_InitStruct);

  /*Configure GPIO pins : PB9 PB8 */
  GPIO_InitStruct.Pin = GPIO_PIN_9|GPIO_PIN_8;
  GPIO_InitStruct.Mode = GPIO_MODE_AF_OD;
  GPIO_InitStruct.Pull = GPIO_NOPULL;
  GPIO_InitStruct.Speed = GPIO_SPEED_FREQ_LOW;
  GPIO_InitStruct.Alternate = GPIO_AF4_I2C1;
  HAL_GPIO_Init(GPIOB, &GPIO_InitStruct);

  /*Configure GPIO pin : PG13 */
  GPIO_InitStruct.Pin = GPIO_PIN_13;
  GPIO_InitStruct.Mode = GPIO_MODE_AF_PP;
  GPIO_InitStruct.Pull = GPIO_NOPULL;
  GPIO_InitStruct.Speed = GPIO_SPEED_FREQ_LOW;
  GPIO_InitStruct.Alternate = GPIO_AF5_SPI6;
  HAL_GPIO_Init(GPIOG, &GPIO_InitStruct);

  /*Configure GPIO pin : PD2 */
  GPIO_InitStruct.Pin = GPIO_PIN_2;
  GPIO_InitStruct.Mode = GPIO_MODE_AF_PP;
  GPIO_InitStruct.Pull = GPIO_NOPULL;
  GPIO_InitStruct.Speed = GPIO_SPEED_FREQ_LOW;
  GPIO_InitStruct.Alternate = GPIO_AF8_UART5;
  HAL_GPIO_Init(GPIOD, &GPIO_InitStruct);

  /*Configure GPIO pin : PD0 */
  GPIO_InitStruct.Pin = GPIO_PIN_0;
  GPIO_InitStruct.Mode = GPIO_MODE_AF_PP;
  GPIO_InitStruct.Pull = GPIO_NOPULL;
  GPIO_InitStruct.Speed = GPIO_SPEED_FREQ_LOW;
  GPIO_InitStruct.Alternate = GPIO_AF9_FDCAN1;
  HAL_GPIO_Init(GPIOD, &GPIO_InitStruct);

  /*Configure GPIO pins : PA10 PA9 PA8 PA12
                           PA11 */
  GPIO_InitStruct.Pin = GPIO_PIN_10|GPIO_PIN_9|GPIO_PIN_8|GPIO_PIN_12
                          |GPIO_PIN_11;
  GPIO_InitStruct.Mode = GPIO_MODE_AF_PP;
  GPIO_InitStruct.Pull = GPIO_NOPULL;
  GPIO_InitStruct.Speed = GPIO_SPEED_FREQ_VERY_HIGH;
  GPIO_InitStruct.Alternate = GPIO_AF2_HRTIM1;
  HAL_GPIO_Init(GPIOA, &GPIO_InitStruct);

  /*Configure GPIO pin : PH13 */
  GPIO_InitStruct.Pin = GPIO_PIN_13;
  GPIO_InitStruct.Mode = GPIO_MODE_AF_PP;
  GPIO_InitStruct.Pull = GPIO_NOPULL;
  GPIO_InitStruct.Speed = GPIO_SPEED_FREQ_LOW;
  GPIO_InitStruct.Alternate = GPIO_AF9_FDCAN1;
  HAL_GPIO_Init(GPIOH, &GPIO_InitStruct);

  /*Configure GPIO pin : PI9 */
  GPIO_InitStruct.Pin = GPIO_PIN_9;
  GPIO_InitStruct.Mode = GPIO_MODE_AF_PP;
  GPIO_InitStruct.Pull = GPIO_NOPULL;
  GPIO_InitStruct.Speed = GPIO_SPEED_FREQ_LOW;
  GPIO_InitStruct.Alternate = GPIO_AF8_UART4;
  HAL_GPIO_Init(GPIOI, &GPIO_InitStruct);

  /*Configure GPIO pins : PC13 PC0 PC1 PC2
                           PC3 PC4 PC5 */
  GPIO_InitStruct.Pin = GPIO_PIN_13|GPIO_PIN_0|GPIO_PIN_1|GPIO_PIN_2
                          |GPIO_PIN_3|GPIO_PIN_4|GPIO_PIN_5;
  GPIO_InitStruct.Mode = GPIO_MODE_ANALOG;
  GPIO_InitStruct.Pull = GPIO_NOPULL;
  HAL_GPIO_Init(GPIOC, &GPIO_InitStruct);

  /*Configure GPIO pin : State_LED_Pin */
  GPIO_InitStruct.Pin = State_LED_Pin;
  GPIO_InitStruct.Mode = GPIO_MODE_OUTPUT_PP;
  GPIO_InitStruct.Pull = GPIO_NOPULL;
  GPIO_InitStruct.Speed = GPIO_SPEED_FREQ_LOW;
  HAL_GPIO_Init(State_LED_GPIO_Port, &GPIO_InitStruct);

  /*Configure GPIO pin : PD1 */
  GPIO_InitStruct.Pin = GPIO_PIN_1;
  GPIO_InitStruct.Mode = GPIO_MODE_AF_PP;
  GPIO_InitStruct.Pull = GPIO_NOPULL;
  GPIO_InitStruct.Speed = GPIO_SPEED_FREQ_LOW;
  GPIO_InitStruct.Alternate = GPIO_AF8_UART4;
  HAL_GPIO_Init(GPIOD, &GPIO_InitStruct);

  /*Configure GPIO pins : PC8 PC7 PC6 */
  GPIO_InitStruct.Pin = GPIO_PIN_8|GPIO_PIN_7|GPIO_PIN_6;
  GPIO_InitStruct.Mode = GPIO_MODE_AF_PP;
  GPIO_InitStruct.Pull = GPIO_NOPULL;
  GPIO_InitStruct.Speed = GPIO_SPEED_FREQ_VERY_HIGH;
  GPIO_InitStruct.Alternate = GPIO_AF1_HRTIM1;
  HAL_GPIO_Init(GPIOC, &GPIO_InitStruct);

  /*Configure GPIO pins : PG7 PG6 */
  GPIO_InitStruct.Pin = GPIO_PIN_7|GPIO_PIN_6;
  GPIO_InitStruct.Mode = GPIO_MODE_AF_PP;
  GPIO_InitStruct.Pull = GPIO_NOPULL;
  GPIO_InitStruct.Speed = GPIO_SPEED_FREQ_VERY_HIGH;
  GPIO_InitStruct.Alternate = GPIO_AF2_HRTIM1;
  HAL_GPIO_Init(GPIOG, &GPIO_InitStruct);

  /*Configure GPIO pins : PF2 PF3 PF5 PF4
                           PF13 PF12 PF11 */
  GPIO_InitStruct.Pin = GPIO_PIN_2|GPIO_PIN_3|GPIO_PIN_5|GPIO_PIN_4
                          |GPIO_PIN_13|GPIO_PIN_12|GPIO_PIN_11;
  GPIO_InitStruct.Mode = GPIO_MODE_ANALOG;
  GPIO_InitStruct.Pull = GPIO_NOPULL;
  HAL_GPIO_Init(GPIOF, &GPIO_InitStruct);

  /*Configure GPIO pins : PF1 PF0 */
  GPIO_InitStruct.Pin = GPIO_PIN_1|GPIO_PIN_0;
  GPIO_InitStruct.Mode = GPIO_MODE_AF_OD;
  GPIO_InitStruct.Pull = GPIO_NOPULL;
  GPIO_InitStruct.Speed = GPIO_SPEED_FREQ_LOW;
  GPIO_InitStruct.Alternate = GPIO_AF4_I2C2;
  HAL_GPIO_Init(GPIOF, &GPIO_InitStruct);

  /*Configure GPIO pins : PK0 PK1 */
  GPIO_InitStruct.Pin = GPIO_PIN_0|GPIO_PIN_1;
  GPIO_InitStruct.Mode = GPIO_MODE_AF_PP;
  GPIO_InitStruct.Pull = GPIO_NOPULL;
  GPIO_InitStruct.Speed = GPIO_SPEED_FREQ_LOW;
  GPIO_InitStruct.Alternate = GPIO_AF1_TIM1;
  HAL_GPIO_Init(GPIOK, &GPIO_InitStruct);

  /*Configure GPIO pin : PF6 */
  GPIO_InitStruct.Pin = GPIO_PIN_6;
  GPIO_InitStruct.Mode = GPIO_MODE_AF_PP;
  GPIO_InitStruct.Pull = GPIO_NOPULL;
  GPIO_InitStruct.Speed = GPIO_SPEED_FREQ_LOW;
  GPIO_InitStruct.Alternate = GPIO_AF7_UART7;
  HAL_GPIO_Init(GPIOF, &GPIO_InitStruct);

  /*Configure GPIO pins : PF7 PF10 */
  GPIO_InitStruct.Pin = GPIO_PIN_7|GPIO_PIN_10;
  GPIO_InitStruct.Mode = GPIO_MODE_AF_PP;
  GPIO_InitStruct.Pull = GPIO_NOPULL;
  GPIO_InitStruct.Speed = GPIO_SPEED_FREQ_LOW;
  GPIO_InitStruct.Alternate = GPIO_AF9_QUADSPI;
  HAL_GPIO_Init(GPIOF, &GPIO_InitStruct);

  /*Configure GPIO pins : PF8 PF9 */
  GPIO_InitStruct.Pin = GPIO_PIN_8|GPIO_PIN_9;
  GPIO_InitStruct.Mode = GPIO_MODE_AF_PP;
  GPIO_InitStruct.Pull = GPIO_NOPULL;
  GPIO_InitStruct.Speed = GPIO_SPEED_FREQ_LOW;
  GPIO_InitStruct.Alternate = GPIO_AF5_SPI5;
  HAL_GPIO_Init(GPIOF, &GPIO_InitStruct);

  /*Configure GPIO pins : PJ11 PJ10 PJ9 PJ8 */
  GPIO_InitStruct.Pin = GPIO_PIN_11|GPIO_PIN_10|GPIO_PIN_9|GPIO_PIN_8;
  GPIO_InitStruct.Mode = GPIO_MODE_AF_PP;
  GPIO_InitStruct.Pull = GPIO_NOPULL;
  GPIO_InitStruct.Speed = GPIO_SPEED_FREQ_LOW;
  GPIO_InitStruct.Alternate = GPIO_AF1_TIM1;
  HAL_GPIO_Init(GPIOJ, &GPIO_InitStruct);

  /*Configure GPIO pin : PH2 */
  GPIO_InitStruct.Pin = GPIO_PIN_2;
  GPIO_InitStruct.Mode = GPIO_MODE_AF_PP;
  GPIO_InitStruct.Pull = GPIO_NOPULL;
  GPIO_InitStruct.Speed = GPIO_SPEED_FREQ_LOW;
  GPIO_InitStruct.Alternate = GPIO_AF1_LPTIM1;
  HAL_GPIO_Init(GPIOH, &GPIO_InitStruct);

  /*Configure GPIO pins : PA2 PA1 PA0 */
  GPIO_InitStruct.Pin = GPIO_PIN_2|GPIO_PIN_1|GPIO_PIN_0;
  GPIO_InitStruct.Mode = GPIO_MODE_AF_PP;
  GPIO_InitStruct.Pull = GPIO_NOPULL;
  GPIO_InitStruct.Speed = GPIO_SPEED_FREQ_LOW;
  GPIO_InitStruct.Alternate = GPIO_AF1_TIM2;
  HAL_GPIO_Init(GPIOA, &GPIO_InitStruct);

  /*Configure GPIO pins : PH3 PH4 PH5 PH9 */
  GPIO_InitStruct.Pin = GPIO_PIN_3|GPIO_PIN_4|GPIO_PIN_5|GPIO_PIN_9;
  GPIO_InitStruct.Mode = GPIO_MODE_ANALOG;
  GPIO_InitStruct.Pull = GPIO_NOPULL;
  HAL_GPIO_Init(GPIOH, &GPIO_InitStruct);

  /*Configure GPIO pins : PF14 PF15 */
  GPIO_InitStruct.Pin = GPIO_PIN_14|GPIO_PIN_15;
  GPIO_InitStruct.Mode = GPIO_MODE_AF_OD;
  GPIO_InitStruct.Pull = GPIO_NOPULL;
  GPIO_InitStruct.Speed = GPIO_SPEED_FREQ_LOW;
  GPIO_InitStruct.Alternate = GPIO_AF4_I2C4;
  HAL_GPIO_Init(GPIOF, &GPIO_InitStruct);

  /*Configure GPIO pin : PB10 */
  GPIO_InitStruct.Pin = GPIO_PIN_10;
  GPIO_InitStruct.Mode = GPIO_MODE_AF_PP;
  GPIO_InitStruct.Pull = GPIO_NOPULL;
  GPIO_InitStruct.Speed = GPIO_SPEED_FREQ_LOW;
  GPIO_InitStruct.Alternate = GPIO_AF9_QUADSPI;
  HAL_GPIO_Init(GPIOB, &GPIO_InitStruct);

  /*Configure GPIO pin : PB11 */
  GPIO_InitStruct.Pin = GPIO_PIN_11;
  GPIO_InitStruct.Mode = GPIO_MODE_AF_PP;
  GPIO_InitStruct.Pull = GPIO_NOPULL;
  GPIO_InitStruct.Speed = GPIO_SPEED_FREQ_LOW;
  GPIO_InitStruct.Alternate = GPIO_AF1_TIM2;
  HAL_GPIO_Init(GPIOB, &GPIO_InitStruct);

  /*Configure GPIO pins : PH10 PH11 PH12 */
  GPIO_InitStruct.Pin = GPIO_PIN_10|GPIO_PIN_11|GPIO_PIN_12;
  GPIO_InitStruct.Mode = GPIO_MODE_AF_PP;
  GPIO_InitStruct.Pull = GPIO_NOPULL;
  GPIO_InitStruct.Speed = GPIO_SPEED_FREQ_LOW;
  GPIO_InitStruct.Alternate = GPIO_AF2_TIM5;
  HAL_GPIO_Init(GPIOH, &GPIO_InitStruct);

  /*Configure GPIO pin : PA6 */
  GPIO_InitStruct.Pin = GPIO_PIN_6;
  GPIO_InitStruct.Mode = GPIO_MODE_AF_PP;
  GPIO_InitStruct.Pull = GPIO_NOPULL;
  GPIO_InitStruct.Speed = GPIO_SPEED_FREQ_LOW;
  GPIO_InitStruct.Alternate = GPIO_AF8_SPI6;
  HAL_GPIO_Init(GPIOA, &GPIO_InitStruct);

  /*Configure GPIO pin : PA7 */
  GPIO_InitStruct.Pin = GPIO_PIN_7;
  GPIO_InitStruct.Mode = GPIO_MODE_AF_PP;
  GPIO_InitStruct.Pull = GPIO_NOPULL;
  GPIO_InitStruct.Speed = GPIO_SPEED_FREQ_LOW;
  GPIO_InitStruct.Alternate = GPIO_AF3_TIM8;
  HAL_GPIO_Init(GPIOA, &GPIO_InitStruct);

  /*Configure GPIO pins : PB2 PB1 PB0 */
  GPIO_InitStruct.Pin = GPIO_PIN_2|GPIO_PIN_1|GPIO_PIN_0;
  GPIO_InitStruct.Mode = GPIO_MODE_ANALOG;
  GPIO_InitStruct.Pull = GPIO_NOPULL;
  HAL_GPIO_Init(GPIOB, &GPIO_InitStruct);

  /*Configure GPIO pin : PE12 */
  GPIO_InitStruct.Pin = GPIO_PIN_12;
  GPIO_InitStruct.Mode = GPIO_MODE_AF_PP;
  GPIO_InitStruct.Pull = GPIO_NOPULL;
  GPIO_InitStruct.Speed = GPIO_SPEED_FREQ_LOW;
  GPIO_InitStruct.Alternate = GPIO_AF13_COMP1;
  HAL_GPIO_Init(GPIOE, &GPIO_InitStruct);

  /*Configure GPIO pins : PD11 PD12 */
  GPIO_InitStruct.Pin = GPIO_PIN_11|GPIO_PIN_12;
  GPIO_InitStruct.Mode = GPIO_MODE_AF_PP;
  GPIO_InitStruct.Pull = GPIO_NOPULL;
  GPIO_InitStruct.Speed = GPIO_SPEED_FREQ_LOW;
  GPIO_InitStruct.Alternate = GPIO_AF3_LPTIM2;
  HAL_GPIO_Init(GPIOD, &GPIO_InitStruct);

  /*Configure GPIO pin : PD13 */
  GPIO_InitStruct.Pin = GPIO_PIN_13;
  GPIO_InitStruct.Mode = GPIO_MODE_AF_PP;
  GPIO_InitStruct.Pull = GPIO_NOPULL;
  GPIO_InitStruct.Speed = GPIO_SPEED_FREQ_LOW;
  GPIO_InitStruct.Alternate = GPIO_AF9_QUADSPI;
  HAL_GPIO_Init(GPIOD, &GPIO_InitStruct);

  /*Configure GPIO pins : PA5 PA4 */
  GPIO_InitStruct.Pin = GPIO_PIN_5|GPIO_PIN_4;
  GPIO_InitStruct.Mode = GPIO_MODE_ANALOG;
  GPIO_InitStruct.Pull = GPIO_NOPULL;
  HAL_GPIO_Init(GPIOA, &GPIO_InitStruct);

  /*Configure GPIO pin : PE8 */
  GPIO_InitStruct.Pin = GPIO_PIN_8;
  GPIO_InitStruct.Mode = GPIO_MODE_AF_PP;
  GPIO_InitStruct.Pull = GPIO_NOPULL;
  GPIO_InitStruct.Speed = GPIO_SPEED_FREQ_LOW;
  GPIO_InitStruct.Alternate = GPIO_AF13_COMP2;
  HAL_GPIO_Init(GPIOE, &GPIO_InitStruct);

  /*Configure GPIO pin : PH6 */
  GPIO_InitStruct.Pin = GPIO_PIN_6;
  GPIO_InitStruct.Mode = GPIO_MODE_AF_PP;
  GPIO_InitStruct.Pull = GPIO_NOPULL;
  GPIO_InitStruct.Speed = GPIO_SPEED_FREQ_LOW;
  GPIO_InitStruct.Alternate = GPIO_AF5_SPI5;
  HAL_GPIO_Init(GPIOH, &GPIO_InitStruct);

  /*Configure GPIO pins : PH8 PH7 */
  GPIO_InitStruct.Pin = GPIO_PIN_8|GPIO_PIN_7;
  GPIO_InitStruct.Mode = GPIO_MODE_AF_OD;
  GPIO_InitStruct.Pull = GPIO_NOPULL;
  GPIO_InitStruct.Speed = GPIO_SPEED_FREQ_LOW;
  GPIO_InitStruct.Alternate = GPIO_AF4_I2C3;
  HAL_GPIO_Init(GPIOH, &GPIO_InitStruct);

  /*Configure GPIO pins : PB12 PB13 */
  GPIO_InitStruct.Pin = GPIO_PIN_12|GPIO_PIN_13;
  GPIO_InitStruct.Mode = GPIO_MODE_AF_PP;
  GPIO_InitStruct.Pull = GPIO_NOPULL;
  GPIO_InitStruct.Speed = GPIO_SPEED_FREQ_LOW;
  GPIO_InitStruct.Alternate = GPIO_AF9_FDCAN2;
  HAL_GPIO_Init(GPIOB, &GPIO_InitStruct);

  /*Configure GPIO pins : PB15 PB14 */
  GPIO_InitStruct.Pin = GPIO_PIN_15|GPIO_PIN_14;
  GPIO_InitStruct.Mode = GPIO_MODE_AF_PP;
  GPIO_InitStruct.Pull = GPIO_NOPULL;
  GPIO_InitStruct.Speed = GPIO_SPEED_FREQ_LOW;
  GPIO_InitStruct.Alternate = GPIO_AF4_USART1;
  HAL_GPIO_Init(GPIOB, &GPIO_InitStruct);

  /*Configure GPIO pins : PD9 PD8 */
  GPIO_InitStruct.Pin = GPIO_PIN_9|GPIO_PIN_8;
  GPIO_InitStruct.Mode = GPIO_MODE_AF_PP;
  GPIO_InitStruct.Pull = GPIO_NOPULL;
  GPIO_InitStruct.Speed = GPIO_SPEED_FREQ_LOW;
  GPIO_InitStruct.Alternate = GPIO_AF7_USART3;
  HAL_GPIO_Init(GPIOD, &GPIO_InitStruct);

  /*Configure GPIO pin : PA3 */
  GPIO_InitStruct.Pin = GPIO_PIN_3;
  GPIO_InitStruct.Mode = GPIO_MODE_AF_PP;
  GPIO_InitStruct.Pull = GPIO_NOPULL;
  GPIO_InitStruct.Speed = GPIO_SPEED_FREQ_LOW;
  GPIO_InitStruct.Alternate = GPIO_AF7_USART2;
  HAL_GPIO_Init(GPIOA, &GPIO_InitStruct);

  /*AnalogSwitch Config */
  HAL_SYSCFG_AnalogSwitchConfig(SYSCFG_SWITCH_PC2, SYSCFG_SWITCH_PC2_OPEN);

  /*AnalogSwitch Config */
  HAL_SYSCFG_AnalogSwitchConfig(SYSCFG_SWITCH_PC3, SYSCFG_SWITCH_PC3_OPEN);

  /*AnalogSwitch Config */
  HAL_SYSCFG_AnalogSwitchConfig(SYSCFG_SWITCH_PA0, SYSCFG_SWITCH_PA0_OPEN);

  /*AnalogSwitch Config */
  HAL_SYSCFG_AnalogSwitchConfig(SYSCFG_SWITCH_PA1, SYSCFG_SWITCH_PA1_OPEN);

}

__weak void Start_StateLED_Toggle(void *argument)
{
  for(;;)
  {
    osDelay(1);
  }
}

__weak void Start_Debug_Task(void *argument)
{
  for(;;)
  {
    osDelay(1);
  }
}

__weak void Start_IWDG_Refresh(void *argument)
{
  for(;;)
  {
    osDelay(1);
  }
}

__weak void Start_Latter_Shell(void *argument)
{
  for(;;)
  {
    osDelay(1);
  }
}

 /* MPU Configuration */

void MPU_Config(void)
{
  MPU_Region_InitTypeDef MPU_InitStruct = {0};

  /* Disables the MPU */
  HAL_MPU_Disable();

  /** Initializes and configures the Region and the memory to be protected
  */
  MPU_InitStruct.Enable = MPU_REGION_ENABLE;
  MPU_InitStruct.Number = MPU_REGION_NUMBER0;
  MPU_InitStruct.BaseAddress = 0x24000000;
  MPU_InitStruct.Size = MPU_REGION_SIZE_512KB;
  MPU_InitStruct.SubRegionDisable = 0;
  MPU_InitStruct.TypeExtField = MPU_TEX_LEVEL1;
  MPU_InitStruct.AccessPermission = MPU_REGION_FULL_ACCESS;
  MPU_InitStruct.DisableExec = MPU_INSTRUCTION_ACCESS_DISABLE;
  MPU_InitStruct.IsShareable = MPU_ACCESS_NOT_SHAREABLE;
  MPU_InitStruct.IsCacheable = MPU_ACCESS_CACHEABLE;
  MPU_InitStruct.IsBufferable = MPU_ACCESS_BUFFERABLE;

  HAL_MPU_ConfigRegion(&MPU_InitStruct);

  /** Initializes and configures the Region and the memory to be protected
  */
  MPU_InitStruct.Number = MPU_REGION_NUMBER1;
  MPU_InitStruct.BaseAddress = 0x30000000;
  MPU_InitStruct.Size = MPU_REGION_SIZE_128KB;
  MPU_InitStruct.SubRegionDisable = 0x0;
  MPU_InitStruct.DisableExec = MPU_INSTRUCTION_ACCESS_ENABLE;
  MPU_InitStruct.IsCacheable = MPU_ACCESS_NOT_CACHEABLE;
  MPU_InitStruct.IsBufferable = MPU_ACCESS_NOT_BUFFERABLE;

  HAL_MPU_ConfigRegion(&MPU_InitStruct);

  /** Initializes and configures the Region and the memory to be protected
  */
  MPU_InitStruct.Number = MPU_REGION_NUMBER2;
  MPU_InitStruct.BaseAddress = 0x30020000;

  HAL_MPU_ConfigRegion(&MPU_InitStruct);

  /** Initializes and configures the Region and the memory to be protected
  */
  MPU_InitStruct.Number = MPU_REGION_NUMBER3;
  MPU_InitStruct.BaseAddress = 0x30040000;
  MPU_InitStruct.Size = MPU_REGION_SIZE_32KB;

  HAL_MPU_ConfigRegion(&MPU_InitStruct);

  /** Initializes and configures the Region and the memory to be protected
  */
  MPU_InitStruct.Number = MPU_REGION_NUMBER4;
  MPU_InitStruct.BaseAddress = 0x38000000;
  MPU_InitStruct.Size = MPU_REGION_SIZE_64KB;
  MPU_InitStruct.DisableExec = MPU_INSTRUCTION_ACCESS_DISABLE;

  HAL_MPU_ConfigRegion(&MPU_InitStruct);
  /* Enables the MPU */
  HAL_MPU_Enable(MPU_PRIVILEGED_DEFAULT);

}

void HAL_TIM_PeriodElapsedCallback(TIM_HandleTypeDef *htim)
{
  if (htim->Instance == TIM17)
  {
    HAL_IncTick();
  }
}

void Error_Handler(void)
{
  __disable_irq();
  while (1)
  {
  }
}
#ifdef USE_FULL_ASSERT
/**
  * @brief  Reports the name of the source file and the source line number
  *         where the assert_param error has occurred.
  * @param  file: pointer to the source file name
  * @param  line: assert_param error line source number
  * @retval None
  */
void assert_failed(uint8_t *file, uint32_t line)
{
  /* USER CODE BEGIN 6 */
  /* User can add his own implementation to report the file name and line number,
  ex: printf("Wrong parameters value: file %s on line %d\r\n", file, line) */
#ifdef DEBUG
  SEGGER_RTT_printf(0, "[ASSERT] Wrong parameters value: file %s on line %d\r\n", file, line);
#endif
  /* USER CODE END 6 */
}
#endif /* USE_FULL_ASSERT */
